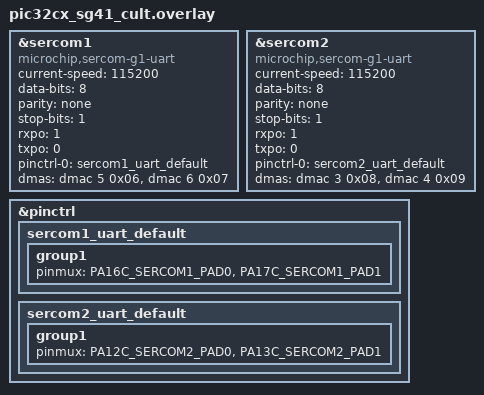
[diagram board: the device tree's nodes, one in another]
/*
 * Copyright (c) 2026 Microchip Technology Inc.
 *
 * SPDX-License-Identifier: Apache-2.0
 */

/* Connect PA16(sercom1 TX) to PA13(sercom2 RX) and PA17(sercom1 RX) to PA12(sercom2 TX) */

dut: &sercom1 {
	compatible = "microchip,sercom-g1-uart";
	#address-cells = <1>;
	#size-cells = <0>;

	current-speed = <115200>;
	data-bits = <8>;
	parity = "none";
	stop-bits = "1";

	rxpo = <1>;
	txpo = <0>;

	pinctrl-0 = <&sercom1_uart_default>;
	pinctrl-names = "default";

	dmas = <&dmac 5 0x06>, <&dmac 6 0x07>;
	dma-names = "rx", "tx";
	status = "okay";
};

dut_aux: &sercom2 {
	compatible = "microchip,sercom-g1-uart";
	#address-cells = <1>;
	#size-cells = <0>;

	current-speed = <115200>;
	data-bits = <8>;
	parity = "none";
	stop-bits = "1";

	rxpo = <1>;
	txpo = <0>;

	pinctrl-0 = <&sercom2_uart_default>;
	pinctrl-names = "default";

	dmas = <&dmac 3 0x08>, <&dmac 4 0x09>;
	dma-names = "rx", "tx";
	status = "okay";
};

&pinctrl {
	sercom1_uart_default: sercom1_uart_default {
		group1 {
			pinmux = <PA16C_SERCOM1_PAD0>,
				 <PA17C_SERCOM1_PAD1>;
		};
	};

	sercom2_uart_default: sercom2_uart_default {
		group1 {
			pinmux = <PA12C_SERCOM2_PAD0>,
				 <PA13C_SERCOM2_PAD1>;
		};
	};
};
